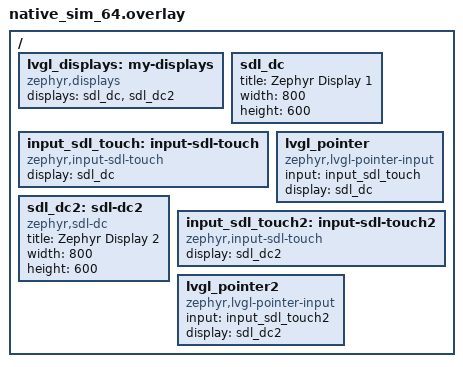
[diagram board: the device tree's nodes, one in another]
/*
 * Copyright (c) 2025, Abderrahmane JARMOUNI
 *
 * SPDX-License-Identifier: Apache-2.0
 */

/ {
	lvgl_displays: my-displays {
		compatible = "zephyr,displays";
		displays = <&sdl_dc &sdl_dc2>;
		status = "okay";
	};

	sdl_dc {
		title = "Zephyr Display 1";
		width = <800>;
		height = <600>;
		status = "okay";
	};

	input_sdl_touch: input-sdl-touch {
		compatible = "zephyr,input-sdl-touch";
		display = <&sdl_dc>;
	};

	lvgl_pointer {
		compatible = "zephyr,lvgl-pointer-input";
		input = <&input_sdl_touch>;
		display = <&sdl_dc>;
		status = "okay";
	};

	sdl_dc2: sdl-dc2 {
		compatible = "zephyr,sdl-dc";
		title = "Zephyr Display 2";
		width = <800>;
		height = <600>;
		status = "okay";
	};

	input_sdl_touch2: input-sdl-touch2 {
		compatible = "zephyr,input-sdl-touch";
		display = <&sdl_dc2>;
	};

	lvgl_pointer2 {
		compatible = "zephyr,lvgl-pointer-input";
		input = <&input_sdl_touch2>;
		display = <&sdl_dc2>;
		status = "okay";
	};
};
